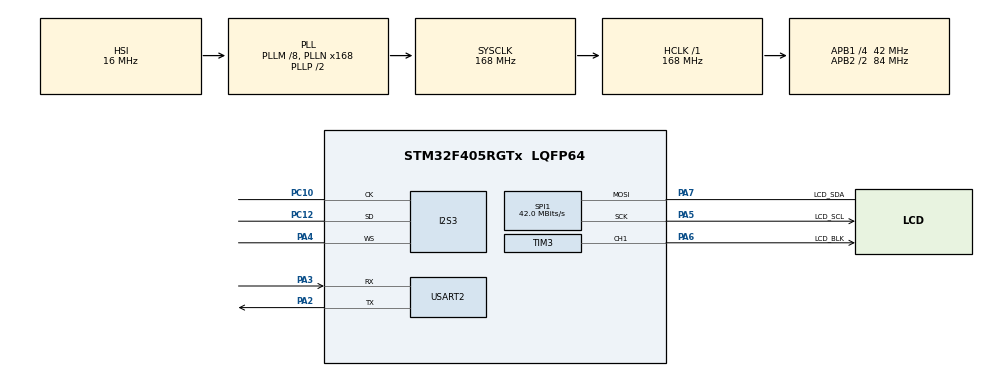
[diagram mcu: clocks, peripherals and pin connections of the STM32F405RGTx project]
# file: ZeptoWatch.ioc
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Dma.Request0=SPI1_TX
Dma.Request1=SPI3_RX
Dma.SPI1_TX.0.Direction=DMA_MEMORY_TO_PERIPH
Dma.SPI1_TX.0.FIFOMode=DMA_FIFOMODE_DISABLE
Dma.SPI1_TX.0.Instance=DMA2_Stream3
Dma.SPI1_TX.0.MemDataAlignment=DMA_MDATAALIGN_BYTE
Dma.SPI1_TX.0.MemInc=DMA_MINC_ENABLE
Dma.SPI1_TX.0.Mode=DMA_NORMAL
Dma.SPI1_TX.0.PeriphDataAlignment=DMA_PDATAALIGN_BYTE
Dma.SPI1_TX.0.PeriphInc=DMA_PINC_DISABLE
Dma.SPI1_TX.0.Priority=DMA_PRIORITY_MEDIUM
Dma.SPI3_RX.1.Direction=DMA_PERIPH_TO_MEMORY
Dma.SPI3_RX.1.FIFOMode=DMA_FIFOMODE_DISABLE
Dma.SPI3_RX.1.Instance=DMA1_Stream0
Dma.SPI3_RX.1.MemDataAlignment=DMA_MDATAALIGN_WORD
Dma.SPI3_RX.1.MemInc=DMA_MINC_ENABLE
Dma.SPI3_RX.1.Mode=DMA_CIRCULAR
Dma.SPI3_RX.1.PeriphDataAlignment=DMA_PDATAALIGN_WORD
Dma.SPI3_RX.1.PeriphInc=DMA_PINC_DISABLE
Dma.SPI3_RX.1.Priority=DMA_PRIORITY_LOW
FREERTOS.Tasks01=lvglTask,2,1024,StartLvglTask,As weak,NULL,Dynamic,NULL,NULL;detectingTask,0,128,StartDetectingTask,As weak,NULL,Dynamic,NULL,NULL
I2S3.DataFormat=I2S_DATAFORMAT_24B
I2S3.ErrorAudioFreq=0.0 %
I2S3.FullDuplexMode=I2S_FULLDUPLEXMODE_DISABLE
I2S3.Instance=SPI$Index
I2S3.Mode=I2S_MODE_MASTER_RX
I2S3.RealAudioFreq=8.0 KHz
I2S3.VirtualMode=I2S_MODE_MASTER
Mcu.Family=STM32F4
Mcu.Name=STM32F405RGTx
Mcu.Package=LQFP64
NVIC.DMA1_Stream0_IRQn=true\:5\:0\:false\:false\:true\:true\:false\:true\:true
NVIC.DMA2_Stream3_IRQn=true\:5\:0\:false\:false\:true\:true\:false\:true\:true
NVIC.PriorityGroup=NVIC_PRIORITYGROUP_4
NVIC.RTC_Alarm_IRQn=true\:5\:0\:false\:false\:true\:true\:true\:true\:true
NVIC.TIM1_UP_TIM10_IRQn=true\:15\:0\:false\:false\:true\:false\:false\:true\:true
NVIC.TIM2_IRQn=true\:5\:0\:false\:false\:true\:true\:true\:true\:true
NVIC.TimeBase=TIM1_UP_TIM10_IRQn
NVIC.TimeBaseIP=TIM1
PA13.Mode=Serial_Wire
PA13.Signal=SYS_JTMS-SWDIO
PA14.Mode=Serial_Wire
PA14.Signal=SYS_JTCK-SWCLK
PA2.Mode=Asynchronous
PA2.Signal=USART2_TX
PA3.Mode=Asynchronous
PA3.Signal=USART2_RX
PA4.GPIO_Mode=GPIO_MODE_AF_PP
PA4.GPIO_PuPd=GPIO_NOPULL
PA4.GPIO_Speed=GPIO_SPEED_FREQ_VERY_HIGH
PA4.Mode=Half_Duplex_Master
PA4.Signal=I2S3_WS
PA5.GPIO_Label=LCD_SCL
PA5.GPIO_PuPd=GPIO_PULLUP
PA5.Mode=Simplex_Bidirectional_Master
PA5.Signal=SPI1_SCK
PA6.GPIO_Label=LCD_BLK
PA6.GPIO_Speed=GPIO_SPEED_FREQ_VERY_HIGH
PA6.Signal=S_TIM3_CH1
PA7.GPIO_Label=LCD_SDA
PA7.GPIO_PuPd=GPIO_PULLUP
PA7.Mode=Simplex_Bidirectional_Master
PA7.Signal=SPI1_MOSI
PC10.GPIO_Mode=GPIO_MODE_AF_PP
PC10.GPIO_PuPd=GPIO_NOPULL
PC10.GPIO_Speed=GPIO_SPEED_FREQ_VERY_HIGH
PC10.Mode=Half_Duplex_Master
PC10.Signal=I2S3_CK
PC12.GPIO_Mode=GPIO_MODE_AF_PP
PC12.GPIO_PuPd=GPIO_NOPULL
PC12.GPIO_Speed=GPIO_SPEED_FREQ_VERY_HIGH
PC12.Mode=Half_Duplex_Master
PC12.Signal=I2S3_SD
PC14-OSC32_IN.Mode=LSE-External-Oscillator
PC14-OSC32_IN.Signal=RCC_OSC32_IN
PC15-OSC32_OUT.Mode=LSE-External-Oscillator
PC15-OSC32_OUT.Signal=RCC_OSC32_OUT
ProjectManager.HeapSize=0x200
ProjectManager.StackSize=0x2000
ProjectManager.TargetToolchain=SW4STM32
RCC.48MHZClocksFreq_Value=84000000
RCC.AHBFreq_Value=168000000
RCC.APB1CLKDivider=RCC_HCLK_DIV4
RCC.APB1Freq_Value=42000000
RCC.APB1TimFreq_Value=84000000
RCC.APB2CLKDivider=RCC_HCLK_DIV2
RCC.APB2Freq_Value=84000000
RCC.APB2TimFreq_Value=168000000
RCC.CortexFreq_Value=168000000
RCC.HCLKFreq_Value=168000000
RCC.HSE_VALUE=25000000
RCC.HSI_VALUE=16000000
RCC.PLLM=8
RCC.PLLN=168
RCC.RCC_RTC_Clock_Source=RCC_RTCCLKSOURCE_LSE
RCC.RCC_RTC_Clock_SourceVirtual=RCC_RTCCLKSOURCE_LSE
RCC.SYSCLKFreq_VALUE=168000000
RCC.SYSCLKSource=RCC_SYSCLKSOURCE_PLLCLK
RCC.VCOOutputFreq_Value=336000000
RTC.Alarm=RTC_ALARM_A
RTC.AlarmMaskDateWeekDay=RTC_ALARMMASK_DATEWEEKDAY
RTC.AlarmMaskHours=RTC_ALARMMASK_HOURS
RTC.AlarmMaskMinutes=RTC_ALARMMASK_MINUTES
RTC.Format=RTC_FORMAT_BIN
RTC.Hours=0
RTC.Seconds_A=1
RTC.Year=0
SH.S_TIM3_CH1.0=TIM3_CH1,PWM Generation1 CH1
SPI1.BaudRatePrescaler=SPI_BAUDRATEPRESCALER_2
SPI1.CLKPhase=SPI_PHASE_2EDGE
SPI1.CLKPolarity=SPI_POLARITY_HIGH
SPI1.CalculateBaudRate=42.0 MBits/s
SPI1.DataSize=SPI_DATASIZE_8BIT
SPI1.Direction=SPI_DIRECTION_1LINE
SPI1.Mode=SPI_MODE_MASTER
SPI1.VirtualType=VM_MASTER
TIM2.Period=100 - 1
TIM2.Prescaler=840 - 1
TIM3.Channel-PWM\ Generation1\ CH1=TIM_CHANNEL_1
TIM3.Period=100 -1
TIM3.Prescaler=1680 - 1
TIM3.Pulse-PWM\ Generation1\ CH1=50
USART2.VirtualMode=VM_ASYNC
VP_FREERTOS_VS_CMSIS_V1.Mode=CMSIS_V1
VP_RTC_VS_RTC_Activate.Mode=RTC_Enabled
VP_RTC_VS_RTC_Alarm_A_Intern.Mode=Alarm A
VP_RTC_VS_RTC_Calendar.Mode=RTC_Calendar
VP_SYS_VS_tim1.Mode=TIM1
VP_TIM2_VS_ClockSourceINT.Mode=Internal
board=custom

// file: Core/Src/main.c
/* USER CODE BEGIN Header */
/**
  ******************************************************************************
  * @file           : main.c
  * @brief          : Main program body
  ******************************************************************************
  * @attention
  *
  * Copyright (c) 2022 STMicroelectronics.
  * All rights reserved.
  *
  * This software is licensed under terms that can be found in the LICENSE file
  * in the root directory of this software component.
  * If no LICENSE file comes with this software, it is provided AS-IS.
  *
  ******************************************************************************
  */
/* USER CODE END Header */
#include "main.h"
#include "cmsis_os.h"
#include "dma.h"
#include "i2s.h"
#include "rtc.h"
#include "spi.h"
#include "tim.h"
#include "usart.h"
#include "gpio.h"

void SystemClock_Config(void);
void MX_FREERTOS_Init(void);

int main(void)
{

  /* MCU Configuration--------------------------------------------------------*/

  /* Reset of all peripherals, Initializes the Flash interface and the Systick. */
  HAL_Init();

  /* Configure the system clock */
  SystemClock_Config();

  /* Initialize all configured peripherals */
  MX_GPIO_Init();
  MX_DMA_Init();
  MX_SPI1_Init();
  MX_RTC_Init();
  MX_TIM2_Init();
  MX_USART2_UART_Init();
  MX_TIM3_Init();
  MX_I2S3_Init();

  /* Call init function for freertos objects (in freertos.c) */
  MX_FREERTOS_Init();

  /* Start scheduler */
  osKernelStart();

  /* We should never get here as control is now taken by the scheduler */
  /* Infinite loop */
	while (1)
	{

	}
}

void SystemClock_Config(void)
{
  RCC_OscInitTypeDef RCC_OscInitStruct = {0};
  RCC_ClkInitTypeDef RCC_ClkInitStruct = {0};

  /** Configure the main internal regulator output voltage
  */
  __HAL_RCC_PWR_CLK_ENABLE();
  __HAL_PWR_VOLTAGESCALING_CONFIG(PWR_REGULATOR_VOLTAGE_SCALE1);

  /** Initializes the RCC Oscillators according to the specified parameters
  * in the RCC_OscInitTypeDef structure.
  */
  RCC_OscInitStruct.OscillatorType = RCC_OSCILLATORTYPE_HSI|RCC_OSCILLATORTYPE_LSE;
  RCC_OscInitStruct.LSEState = RCC_LSE_ON;
  RCC_OscInitStruct.HSIState = RCC_HSI_ON;
  RCC_OscInitStruct.HSICalibrationValue = RCC_HSICALIBRATION_DEFAULT;
  RCC_OscInitStruct.PLL.PLLState = RCC_PLL_ON;
  RCC_OscInitStruct.PLL.PLLSource = RCC_PLLSOURCE_HSI;
  RCC_OscInitStruct.PLL.PLLM = 8;
  RCC_OscInitStruct.PLL.PLLN = 168;
  RCC_OscInitStruct.PLL.PLLP = RCC_PLLP_DIV2;
  RCC_OscInitStruct.PLL.PLLQ = 4;
  if (HAL_RCC_OscConfig(&RCC_OscInitStruct) != HAL_OK)
  {
    Error_Handler();
  }

  /** Initializes the CPU, AHB and APB buses clocks
  */
  RCC_ClkInitStruct.ClockType = RCC_CLOCKTYPE_HCLK|RCC_CLOCKTYPE_SYSCLK
                              |RCC_CLOCKTYPE_PCLK1|RCC_CLOCKTYPE_PCLK2;
  RCC_ClkInitStruct.SYSCLKSource = RCC_SYSCLKSOURCE_PLLCLK;
  RCC_ClkInitStruct.AHBCLKDivider = RCC_SYSCLK_DIV1;
  RCC_ClkInitStruct.APB1CLKDivider = RCC_HCLK_DIV4;
  RCC_ClkInitStruct.APB2CLKDivider = RCC_HCLK_DIV2;

  if (HAL_RCC_ClockConfig(&RCC_ClkInitStruct, FLASH_LATENCY_5) != HAL_OK)
  {
    Error_Handler();
  }
}

/* USER CODE BEGIN 4 */
#include "lvgl.h"
/* USER CODE END 4 */

void HAL_TIM_PeriodElapsedCallback(TIM_HandleTypeDef *htim)
{
  if (htim->Instance == TIM1) {
    HAL_IncTick();
  }
  /* USER CODE BEGIN Callback 1 */
	if (htim == &htim2) {
		lv_tick_inc(1);
	}
  /* USER CODE END Callback 1 */
}

void Error_Handler(void)
{
	__disable_irq();
	while (1)
	{
	}
}

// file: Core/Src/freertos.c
/* USER CODE BEGIN Header */
/**
  ******************************************************************************
  * File Name          : freertos.c
  * Description        : Code for freertos applications
  ******************************************************************************
  * @attention
  *
  * Copyright (c) 2022 STMicroelectronics.
  * All rights reserved.
  *
  * This software is licensed under terms that can be found in the LICENSE file
  * in the root directory of this software component.
  * If no LICENSE file comes with this software, it is provided AS-IS.
  *
  ******************************************************************************
  */
/* USER CODE END Header */

#include "FreeRTOS.h"
#include "task.h"
#include "main.h"
#include "cmsis_os.h"

osThreadId lvglTaskHandle;
osThreadId detectingTaskHandle;

void StartLvglTask(void const * argument);
void StartDetectingTask(void const * argument);

void MX_FREERTOS_Init(void); /* (MISRA C 2004 rule 8.1) */

/* GetIdleTaskMemory prototype (linked to static allocation support) */
void vApplicationGetIdleTaskMemory( StaticTask_t **ppxIdleTaskTCBBuffer, StackType_t **ppxIdleTaskStackBuffer, uint32_t *pulIdleTaskStackSize );

/* USER CODE BEGIN GET_IDLE_TASK_MEMORY */
static StaticTask_t xIdleTaskTCBBuffer;
static StackType_t xIdleStack[configMINIMAL_STACK_SIZE];

void vApplicationGetIdleTaskMemory( StaticTask_t **ppxIdleTaskTCBBuffer, StackType_t **ppxIdleTaskStackBuffer, uint32_t *pulIdleTaskStackSize )
{
	*ppxIdleTaskTCBBuffer = &xIdleTaskTCBBuffer;
	*ppxIdleTaskStackBuffer = &xIdleStack[0];
	*pulIdleTaskStackSize = configMINIMAL_STACK_SIZE;
	/* place for user code */
}
/* USER CODE END GET_IDLE_TASK_MEMORY */

void MX_FREERTOS_Init(void) {

	/* Create the thread(s) */
	/* definition and creation of lvglTask */
	osThreadDef(lvglTask, StartLvglTask, osPriorityHigh, 0, 1024);
	lvglTaskHandle = osThreadCreate(osThread(lvglTask), NULL);

	/* definition and creation of detectingTask */
	osThreadDef(detectingTask, StartDetectingTask, osPriorityNormal, 0, 128);
	detectingTaskHandle = osThreadCreate(osThread(detectingTask), NULL);

}

__weak void StartLvglTask(void const * argument)
{
	for(;;)
	{
		osDelay(1);
	}
}

__weak void StartDetectingTask(void const * argument)
{
	for(;;)
	{
		osDelay(1);
	}
}
